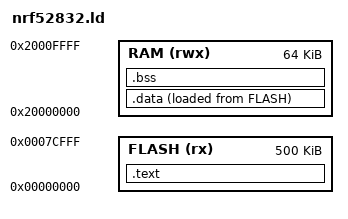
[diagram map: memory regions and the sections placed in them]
/* Code is limited to 0x7CFFF. Reserved pages:
 * 0x7D000 - setpoint storage
 * 0x7F000 - pair record storage
 */
MEMORY
{
    FLASH (rx) : ORIGIN = 0x00000000, LENGTH = 0x7D000
    RAM (rwx)  : ORIGIN = 0x20000000, LENGTH = 64K
}

_estack = ORIGIN(RAM) + LENGTH(RAM);

SECTIONS
{
    .text :
    {
        KEEP(*(.vectors))
        *(.text*)
        *(.rodata*)
        . = ALIGN(4);
        _etext = .;
    } > FLASH

    _sidata = LOADADDR(.data);

    .data :
    {
        . = ALIGN(4);
        _sdata = .;
        *(.data*)
        . = ALIGN(4);
        _edata = .;
    } > RAM AT > FLASH

    .bss (NOLOAD) :
    {
        . = ALIGN(4);
        _sbss = .;
        *(.bss*)
        *(COMMON)
        . = ALIGN(4);
        _ebss = .;
    } > RAM
}
